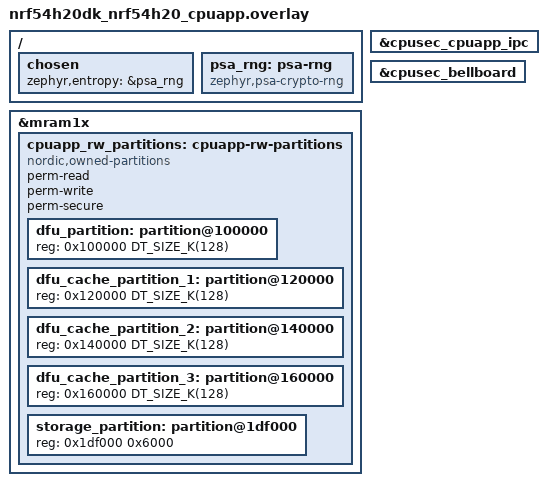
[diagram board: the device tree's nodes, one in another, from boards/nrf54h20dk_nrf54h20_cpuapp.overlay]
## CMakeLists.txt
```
#
# Copyright (c) 2023 Nordic Semiconductor
#
# SPDX-License-Identifier: LicenseRef-Nordic-5-Clause
#

cmake_minimum_required(VERSION 3.20.0)

find_package(Zephyr REQUIRED HINTS $ENV{ZEPHYR_BASE})
project(dfu_target_suit_test)

FILE(GLOB app_sources src/*.c)
target_sources(app PRIVATE ${app_sources})

set(includes
"src/"
)

target_include_directories(app
  PRIVATE
  ${ZEPHYR_NRF_MODULE_DIR}/subsys/dfu/include
  ${includes}
  )

# Mandatory stubbed flags for building test setup
target_compile_options(app
  PRIVATE
  -DCONFIG_DFU_TARGET_LOG_LEVEL=2
  -DCONFIG_DFU_TARGET_SMP=1
  -DCONFIG_DFU_TARGET_SMP_IMAGE_LIST_SIZE=2
  )
```

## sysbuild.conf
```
#
# Copyright (c) 2024 Nordic Semiconductor ASA
#
# SPDX-License-Identifier: LicenseRef-Nordic-5-Clause
#

# SB_CONFIG_SUIT_ENVELOPE=y
```

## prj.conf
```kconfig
#
# Copyright (c) 2024 Nordic Semiconductor ASA
#
# SPDX-License-Identifier: LicenseRef-Nordic-5-Clause
#
CONFIG_ZTEST=y

# Enable suit
CONFIG_SUIT=y
CONFIG_SUIT_DFU=y

# Enable dfu_target
CONFIG_DFU_TARGET=y
CONFIG_DFU_TARGET_SUIT=y

# Initialize SUIT DFU by dfu_target since it is the only 
# one SUIT DFU implementation in use
CONFIG_DFU_TARGET_SUIT_INITIALIZE_SUIT=y

# Choose SUIT platform APP
CONFIG_SUIT_PLATFORM_VARIANT_APP=y
```

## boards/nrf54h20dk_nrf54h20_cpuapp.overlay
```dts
/*
 * Copyright (c) 2024 Nordic Semiconductor ASA
 *
 * SPDX-License-Identifier: LicenseRef-Nordic-5-Clause
 */

/ {
	chosen {
		zephyr,entropy = &psa_rng;
	};

	psa_rng: psa-rng {
		compatible = "zephyr,psa-crypto-rng";
		status = "okay";
	};
};

/* Split DFU partition into a smaller one and DFU caches. */
/delete-node/ &dfu_partition;
/delete-node/ &storage_partition;

&mram1x {
	cpuapp_rw_partitions: cpuapp-rw-partitions {
		compatible = "nordic,owned-partitions", "fixed-partitions";
		status = "okay";
		perm-read;
		perm-write;
		perm-secure;
		#address-cells = < 0x1 >;
		#size-cells = < 0x1 >;

		dfu_partition: partition@100000 {
			reg = < 0x100000 DT_SIZE_K(128) >;
		};

		dfu_cache_partition_1: partition@120000 {
			reg = <0x120000 DT_SIZE_K(128)>;
		};

		dfu_cache_partition_2: partition@140000 {
			reg = <0x140000 DT_SIZE_K(128)>;
		};

		dfu_cache_partition_3: partition@160000 {
			reg = <0x160000 DT_SIZE_K(128)>;
		};

		storage_partition: partition@1df000 {
			reg = < 0x1df000 0x6000 >;
		};
	};
};

/* Communication between Application Core and Secure domain for SUIT */
&cpusec_cpuapp_ipc {
	status = "okay";
};
&cpusec_bellboard {
	status = "okay";
};
```

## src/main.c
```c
/*
 * Copyright (c) 2023 Nordic Semiconductor ASA
 *
 * SPDX-License-Identifier: LicenseRef-Nordic-5-Clause
 */

#include <zephyr/ztest.h>
#include <dfu/dfu_target.h>
#include <dfu/dfu_target_suit.h>
#include <zephyr/devicetree.h>

#define TEST_IMAGE_SIZE		1024
#define TEST_IMAGE_ENVELOPE_NUM 0
#define TEST_IMAGE_APP_NUM	2

static uint8_t dfu_target_buffer[TEST_IMAGE_SIZE];

/* The SUIT envelopes are defined inside the respective manfest_*.c files. */
extern uint8_t manifest[];
extern const size_t manifest_len;
extern uint8_t dfu_cache_partition_1[];
extern const size_t dfu_cache_partition_1_len;

ZTEST(dfu_target_suit, test_image_init)
{
	int rc;

	rc = dfu_target_suit_reset();
	zassert_equal(rc, 0, "Unexpected failure: %d", rc);

	rc = dfu_target_init(DFU_TARGET_IMAGE_TYPE_SUIT, TEST_IMAGE_ENVELOPE_NUM, TEST_IMAGE_SIZE,
			     NULL);
	zassert_equal(rc, -ENODEV,
		      "dfu_target should fail because the buffer has not been initialized. %d", rc);

	rc = dfu_target_suit_set_buf(dfu_target_buffer, sizeof(dfu_target_buffer));
	zassert_equal(rc, 0, "dfu_target should initialize the data buffer %d", rc);

	rc = dfu_target_init(DFU_TARGET_IMAGE_TYPE_SUIT, TEST_IMAGE_ENVELOPE_NUM,
			     TEST_IMAGE_SIZE * 1000, NULL);
	zassert_equal(rc, -EFBIG, "dfu_target should not allow too big files. %d", rc);

	rc = dfu_target_init(DFU_TARGET_IMAGE_TYPE_SUIT, TEST_IMAGE_ENVELOPE_NUM, TEST_IMAGE_SIZE,
			     NULL);
	zassert_equal(rc, 0, "Unexpected failure: %d", rc);

	rc = dfu_target_init(DFU_TARGET_IMAGE_TYPE_SUIT, TEST_IMAGE_ENVELOPE_NUM, TEST_IMAGE_SIZE,
			     NULL);
	zassert_equal(rc, -EBUSY,
		      "dfu_target should not initialize the same image twice until the stream is "
		      "not ended or reset. %d",
		      rc);

	rc = dfu_target_suit_reset();
	zassert_equal(rc, 0, "Unexpected failure: %d", rc);

	rc = dfu_target_init(DFU_TARGET_IMAGE_TYPE_SUIT, TEST_IMAGE_APP_NUM, TEST_IMAGE_SIZE, NULL);
	zassert_equal(rc, 0, "Unexpected failure: %d", rc);
}

ZTEST(dfu_target_suit, test_image_upload)
{
	int rc;
	size_t offset = 0;

	rc = dfu_target_suit_reset();
	zassert_equal(rc, 0, "Unexpected failure: %d", rc);

	rc = dfu_target_suit_write(manifest, TEST_IMAGE_SIZE);
	zassert_equal(rc, -EFAULT, "Unexpected failure: %d", rc);

	rc = dfu_target_suit_schedule_update(0);
	zassert_equal(rc, -ENOTSUP,
		      "scheduling update should file because there is no manifest stored yet: %d",
		      rc);

	rc = dfu_target_suit_offset_get(&offset);
	zassert_equal(rc, 0, "Unexpected failure: %d", rc);
	zassert_equal(offset, 0, "DFU target offset should be equal to 0");

	rc = dfu_target_init(DFU_TARGET_IMAGE_TYPE_SUIT, TEST_IMAGE_ENVELOPE_NUM, manifest_len,
			     NULL);
	zassert_equal(rc, 0, "Unexpected failure: %d", rc);

	rc = dfu_target_suit_write(manifest, manifest_len);
	zassert_equal(rc, 0, "Unexpected failure: %d", rc);

	rc = dfu_target_suit_offset_get(&offset);
	zassert_equal(rc, 0, "DFU target offset get should pass for image 0 %d", rc);
	zassert_equal(offset, manifest_len, "DFU target offset should be equal to image size");

	rc = dfu_target_done(true);
	zassert_equal(rc, 0, "Unexpected failure: %d", rc);

	rc = dfu_target_init(DFU_TARGET_IMAGE_TYPE_SUIT, TEST_IMAGE_APP_NUM,
			     dfu_cache_partition_1_len, NULL);
	zassert_equal(rc, 0, "Unexpected failure: %d", rc);

	rc = dfu_target_suit_write(dfu_cache_partition_1, dfu_cache_partition_1_len);
	zassert_equal(rc, 0, "Unexpected failure: %d", rc);

	rc = dfu_target_suit_offset_get(&offset);
	zassert_equal(rc, 0, "DFU target offset get should pass for image 0 %d", rc);
	zassert_equal(offset, dfu_cache_partition_1_len,
		      "DFU target offset should be equal to image size");

	rc = dfu_target_done(true);
	zassert_equal(rc, 0, "Unexpected failure: %d", rc);

	rc = dfu_target_suit_schedule_update(0);
	zassert_equal(rc, 0, "Unexpected failure: %d", rc);
}

ZTEST_SUITE(dfu_target_suit, NULL, NULL, NULL, NULL, NULL);
```

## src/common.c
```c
/*
 * Copyright (c) 2024 Nordic Semiconductor ASA
 *
 * SPDX-License-Identifier: LicenseRef-Nordic-5-Clause
 */

#include "common.h"

/* Mocks - ssf services have to be mocked, as real communication with secure domain
 * cannot take place in these tests because native_posix target does not have the secure domain
 * to communicate with, and nRF54H should not reset the device after calling
 * the dfu_target_suit_schedule_update function.
 */
DEFINE_FFF_GLOBALS;

/* Mocks of functions provided via SSF services */
#ifdef CONFIG_SOC_POSIX
FAKE_VALUE_FUNC(int, suit_plat_component_compatibility_check, suit_manifest_class_id_t *,
		struct zcbor_string *);
FAKE_VALUE_FUNC(int, suit_plat_authorize_sequence_num, enum suit_command_sequence,
		struct zcbor_string *, unsigned int);
FAKE_VALUE_FUNC(int, suit_plat_authorize_unsigned_manifest, struct zcbor_string *);
FAKE_VALUE_FUNC(int, suit_plat_authenticate_manifest, struct zcbor_string *, enum suit_cose_alg,
		struct zcbor_string *, struct zcbor_string *, struct zcbor_string *);

FAKE_VALUE_FUNC(suit_ssf_err_t, suit_check_installed_component_digest, suit_plat_mreg_t *, int,
		suit_plat_mreg_t *);
FAKE_VALUE_FUNC(suit_ssf_err_t, suit_get_supported_manifest_roles, suit_manifest_role_t *,
		size_t *);
FAKE_VALUE_FUNC(suit_ssf_err_t, suit_get_supported_manifest_info, suit_manifest_role_t,
		suit_ssf_manifest_class_info_t *);
FAKE_VALUE_FUNC(suit_ssf_err_t, suit_get_installed_manifest_info, suit_manifest_class_id_t *,
		unsigned int *, suit_semver_raw_t *, suit_digest_status_t *, int *,
		suit_plat_mreg_t *);
#endif

DEFINE_FAKE_VALUE_FUNC(int, suit_trigger_update, suit_plat_mreg_t *, size_t);

void reset_fakes(void)
{
	#ifdef CONFIG_SOC_POSIX
		RESET_FAKE(suit_plat_component_compatibility_check);
		RESET_FAKE(suit_plat_authorize_sequence_num);
		RESET_FAKE(suit_plat_authorize_unsigned_manifest);
		RESET_FAKE(suit_plat_authenticate_manifest);
		RESET_FAKE(suit_check_installed_component_digest);
		RESET_FAKE(suit_get_supported_manifest_roles);
		RESET_FAKE(suit_get_supported_manifest_info);
		RESET_FAKE(suit_get_installed_manifest_info);
	#endif /* CONFIG_SOC_POSIX */
	
	RESET_FAKE(suit_trigger_update);
}
```

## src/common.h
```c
/*
 * Copyright (c) 2024 Nordic Semiconductor ASA
 *
 * SPDX-License-Identifier: LicenseRef-Nordic-5-Clause
 */

#ifndef DFU_TARGET_SUIT_TEST_COMMON_H__
#define DFU_TARGET_SUIT_TEST_COMMON_H__

#include <stdint.h>
#include <stddef.h>

#include <sdfw/sdfw_services/suit_service.h>
#include <suit_plat_mem_util.h>
#include <suit_platform.h>

#include <zephyr/ztest.h>
#include <zephyr/devicetree.h>
#include <zephyr/fff.h>

/**
 * @brief Reset all mocked functions.
 *
 */
void reset_fakes(void);

DECLARE_FAKE_VALUE_FUNC(int, suit_trigger_update, suit_plat_mreg_t *, size_t);

#endif // DFU_TARGET_SUIT_TEST_COMMON_H__
```

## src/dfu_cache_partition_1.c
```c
/*
 * Copyright (c) 2024 Nordic Semiconductor ASA
 *
 * SPDX-License-Identifier: LicenseRef-Nordic-5-Clause
 */

#include <stdint.h>
#include <stddef.h>

uint8_t dfu_cache_partition_1[] = {
	0xBF, 0x69, 0x23, 0x66, 0x69, 0x6C, 0x65, 0x2E, 0x62, 0x69, 0x6E, 0x5A, 0x00, 0x00, 0x01,
	0x00, 0xC7, 0x9C, 0xAB, 0x9D, 0xE8, 0x33, 0x7F, 0x30, 0x14, 0xEB, 0xAC, 0x02, 0xAF, 0x26,
	0x01, 0x5E, 0x80, 0x6D, 0x88, 0xA1, 0xDB, 0x11, 0xA7, 0x31, 0xDF, 0xA6, 0xEC, 0xCB, 0x9B,
	0x48, 0x0D, 0xC8, 0x34, 0x40, 0x6D, 0x30, 0x86, 0x7D, 0xE8, 0x1B, 0xEC, 0x3C, 0xF5, 0x40,
	0xD0, 0x48, 0x18, 0x82, 0x11, 0x9D, 0x7C, 0x3F, 0x6C, 0xE5, 0x8F, 0xF1, 0xD3, 0x5D, 0xE1,
	0x51, 0xF7, 0x6A, 0x0F, 0xAF, 0x0B, 0xBD, 0x4C, 0x5F, 0xA5, 0x34, 0x1A, 0x66, 0xDB, 0x22,
	0xEC, 0x63, 0xED, 0x4B, 0xAB, 0xC7, 0xC8, 0xF7, 0x59, 0xD8, 0xD6, 0x9E, 0xEC, 0x71, 0x1B,
	0x24, 0x20, 0xB9, 0xAE, 0xE1, 0x3B, 0xFC, 0xAE, 0xB8, 0x77, 0xAC, 0xA4, 0x57, 0x34, 0x97,
	0x84, 0x4F, 0x58, 0xD5, 0x68, 0x08, 0x6F, 0xE3, 0x9C, 0x7E, 0x1B, 0xD7, 0x38, 0x22, 0x98,
	0x48, 0xF8, 0x7A, 0x67, 0xB2, 0xD9, 0xAC, 0xC5, 0x34, 0xC1, 0x27, 0x82, 0x8E, 0x42, 0x79,
	0x84, 0x21, 0x37, 0x4C, 0x41, 0x4A, 0x0F, 0xE2, 0x7F, 0xA0, 0x6A, 0x19, 0x13, 0x3D, 0x52,
	0x22, 0x7F, 0xD6, 0x2F, 0x71, 0x12, 0x76, 0xAB, 0x25, 0x9C, 0xFC, 0x67, 0x08, 0x03, 0x7C,
	0xDB, 0x18, 0xE6, 0x45, 0xF8, 0x99, 0xC2, 0x9E, 0x2C, 0xE3, 0x9B, 0x25, 0xA9, 0x7B, 0x09,
	0xFF, 0x00, 0x57, 0x26, 0x08, 0x0A, 0x11, 0x42, 0xCF, 0x82, 0xA2, 0x6B, 0x2A, 0x99, 0xF9,
	0x71, 0x9D, 0x14, 0x19, 0x5C, 0x5C, 0x78, 0x31, 0x60, 0x42, 0x4A, 0x18, 0x1F, 0xEC, 0x78,
	0x6A, 0x9A, 0x7C, 0x4F, 0xCF, 0xE8, 0x5A, 0x29, 0x65, 0xCD, 0x01, 0x3B, 0x6D, 0x53, 0xBB,
	0xC6, 0xDB, 0xDA, 0xD5, 0x8F, 0xF7, 0xF4, 0xD9, 0xB9, 0x0A, 0x03, 0x4B, 0xFF, 0x33, 0xAB,
	0x3B, 0xC5, 0xAF, 0xD0, 0xB8, 0x2C, 0x0F, 0x6A, 0xA9, 0x11, 0xB0, 0xE8, 0x57, 0x8C, 0x92,
	0x53, 0x81, 0xFF};

const size_t dfu_cache_partition_1_len = sizeof(dfu_cache_partition_1);
```

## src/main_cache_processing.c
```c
/*
 * Copyright (c) 2024 Nordic Semiconductor ASA
 *
 * SPDX-License-Identifier: LicenseRef-Nordic-5-Clause
 */

#if CONFIG_TESTS_SUIT_DFU_TARGET_SUIT_CACHE_PROCESSING

#include <dfu/dfu_target.h>
#include <dfu/dfu_target_suit.h>

#include "common.h"

/* The SUIT envelopes are defined inside the respective manfest_*.c files. */
extern uint8_t manifest[];
extern const size_t manifest_len;
extern uint8_t dfu_cache_partition_1[];
extern const size_t dfu_cache_partition_1_len;
extern uint8_t manifest_with_payload[];
extern const size_t manifest_with_payload_len;

#define TEST_IMAGE_SIZE		1024
#define TEST_IMAGE_ENVELOPE_NUM 0
#define TEST_IMAGE_APP_NUM	2

static uint8_t dfu_target_buffer[TEST_IMAGE_SIZE];

static void setup_test(void *f)
{
	(void)f;

	reset_fakes();
}

ZTEST(dfu_target_suit, test_image_init)
{
	int rc;

	rc = dfu_target_suit_reset();
	zassert_equal(rc, 0, "Unexpected failure: %d", rc);

	rc = dfu_target_init(DFU_TARGET_IMAGE_TYPE_SUIT, TEST_IMAGE_ENVELOPE_NUM, TEST_IMAGE_SIZE,
			     NULL);
	zassert_equal(rc, -ENODEV,
		      "dfu_target should fail because the buffer has not been initialized. %d", rc);

	rc = dfu_target_suit_set_buf(dfu_target_buffer, sizeof(dfu_target_buffer));
	zassert_equal(rc, 0, "dfu_target should initialize the data buffer %d", rc);

	rc = dfu_target_init(DFU_TARGET_IMAGE_TYPE_SUIT, TEST_IMAGE_ENVELOPE_NUM,
			     TEST_IMAGE_SIZE * 1000, NULL);
	zassert_equal(rc, -EFBIG, "dfu_target should not allow too big files. %d", rc);

	rc = dfu_target_init(DFU_TARGET_IMAGE_TYPE_SUIT, TEST_IMAGE_ENVELOPE_NUM, TEST_IMAGE_SIZE,
			     NULL);
	zassert_equal(rc, 0, "Unexpected failure: %d", rc);

	rc = dfu_target_init(DFU_TARGET_IMAGE_TYPE_SUIT, TEST_IMAGE_ENVELOPE_NUM, TEST_IMAGE_SIZE,
			     NULL);
	zassert_equal(rc, -EBUSY,
		      "dfu_target should not initialize the same image twice until the stream is "
		      "not ended or reset. %d",
		      rc);

	rc = dfu_target_suit_reset();
	zassert_equal(rc, 0, "Unexpected failure: %d", rc);

	rc = dfu_target_init(DFU_TARGET_IMAGE_TYPE_SUIT, TEST_IMAGE_APP_NUM, TEST_IMAGE_SIZE, NULL);
	zassert_equal(rc, 0, "Unexpected failure: %d", rc);
}

ZTEST(dfu_target_suit, test_image_upload)
{
	int rc;
	size_t offset = 0;

	rc = dfu_target_suit_reset();
	zassert_equal(rc, 0, "Unexpected failure: %d", rc);

	rc = dfu_target_suit_write(manifest, TEST_IMAGE_SIZE);
	zassert_equal(rc, -EFAULT, "Unexpected failure: %d", rc);

	rc = dfu_target_suit_schedule_update(0);
	zassert_equal(rc, -ENOTSUP,
		      "scheduling update should file because there is no manifest stored yet: %d",
		      rc);

	rc = dfu_target_suit_offset_get(&offset);
	zassert_equal(rc, 0, "Unexpected failure: %d", rc);
	zassert_equal(offset, 0, "DFU target offset should be equal to 0");

	rc = dfu_target_init(DFU_TARGET_IMAGE_TYPE_SUIT, TEST_IMAGE_ENVELOPE_NUM, manifest_len,
			     NULL);
	zassert_equal(rc, 0, "Unexpected failure: %d", rc);

	rc = dfu_target_suit_write(manifest, manifest_len);
	zassert_equal(rc, 0, "Unexpected failure: %d", rc);

	rc = dfu_target_suit_offset_get(&offset);
	zassert_equal(rc, 0, "DFU target offset get should pass for image 0 %d", rc);
	zassert_equal(offset, manifest_len, "DFU target offset should be equal to image size");

	rc = dfu_target_done(true);
	zassert_equal(rc, 0, "Unexpected failure: %d", rc);

	rc = dfu_target_init(DFU_TARGET_IMAGE_TYPE_SUIT, TEST_IMAGE_APP_NUM,
			     dfu_cache_partition_1_len, NULL);
	zassert_equal(rc, 0, "Unexpected failure: %d", rc);

	rc = dfu_target_suit_write(dfu_cache_partition_1, dfu_cache_partition_1_len);
	zassert_equal(rc, 0, "Unexpected failure: %d", rc);

	rc = dfu_target_suit_offset_get(&offset);
	zassert_equal(rc, 0, "DFU target offset get should pass for image 0 %d", rc);
	zassert_equal(offset, dfu_cache_partition_1_len,
		      "DFU target offset should be equal to image size");

	rc = dfu_target_done(true);
	zassert_equal(rc, 0, "Unexpected failure: %d", rc);

	rc = dfu_target_suit_schedule_update(0);
	zassert_equal(rc, 0, "Unexpected failure: %d", rc);

	dfu_target_suit_reboot();
	zassert_equal(suit_trigger_update_fake.call_count, 1,
		      "Incorrect number of suit_dfu_update_start() calls");
}

ZTEST_SUITE(dfu_target_suit, NULL, NULL, setup_test, NULL, NULL);

#endif /* CONFIG_TESTS_SUIT_DFU_TARGET_SUIT_CACHE_PROCESSING */
```

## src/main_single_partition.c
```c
/*
 * Copyright (c) 2024 Nordic Semiconductor ASA
 *
 * SPDX-License-Identifier: LicenseRef-Nordic-5-Clause
 */

#if CONFIG_TESTS_SUIT_DFU_TARGET_SUIT_SINGLE_PARTITION

#include <dfu/dfu_target.h>
#include <dfu/dfu_target_suit.h>

#include "common.h"

/* The SUIT envelopes are defined inside the respective manfest_*.c files. */
extern uint8_t manifest[];
extern const size_t manifest_len;

#define TEST_IMAGE_SIZE		 1024
#define TEST_IMAGE_ENVELOPE_NUM	 0
#define TEST_WRONG_IMAGE_CACHE_0 1
#define TEST_WRONG_IMAGE_CACHE_1 2

static uint8_t dfu_target_buffer[TEST_IMAGE_SIZE];

static void setup_test(void *f)
{
	(void)f;

	reset_fakes();
}

ZTEST(dfu_target_suit, test_image_init)
{
	int rc;

	rc = dfu_target_suit_reset();
	zassert_equal(rc, 0, "Unexpected failure: %d", rc);

	rc = dfu_target_init(DFU_TARGET_IMAGE_TYPE_SUIT, TEST_IMAGE_ENVELOPE_NUM, TEST_IMAGE_SIZE,
			     NULL);
	zassert_equal(rc, -ENODEV,
		      "dfu_target should fail because the buffer has not been initialized. %d", rc);

	rc = dfu_target_suit_set_buf(dfu_target_buffer, sizeof(dfu_target_buffer));
	zassert_equal(rc, 0, "dfu_target should initialize the data buffer %d", rc);

	rc = dfu_target_init(DFU_TARGET_IMAGE_TYPE_SUIT, TEST_IMAGE_ENVELOPE_NUM, TEST_IMAGE_SIZE,
			     NULL);
	zassert_equal(rc, 0, "Unexpected failure: %d", rc);

	rc = dfu_target_init(DFU_TARGET_IMAGE_TYPE_SUIT, TEST_WRONG_IMAGE_CACHE_0, TEST_IMAGE_SIZE,
			     NULL);
	zassert_equal(rc, -ENOTSUP,
		      "dfu_target should fail because CACHE PROCESSING is not enabled: %d", rc);

	rc = dfu_target_init(DFU_TARGET_IMAGE_TYPE_SUIT, TEST_WRONG_IMAGE_CACHE_1, TEST_IMAGE_SIZE,
			     NULL);
	zassert_equal(rc, -ENOTSUP,
		      "dfu_target should fail because CACHE PROCESSING is not enabled: %d", rc);
}

ZTEST(dfu_target_suit, test_upload)
{
	int rc;
	size_t offset = 0;

	rc = dfu_target_suit_reset();
	zassert_equal(rc, 0, "Unexpected failure: %d", rc);

	rc = dfu_target_suit_set_buf(dfu_target_buffer, sizeof(dfu_target_buffer));
	zassert_equal(rc, 0, "dfu_target should initialize the data buffer %d", rc);

	rc = dfu_target_init(DFU_TARGET_IMAGE_TYPE_SUIT, TEST_IMAGE_ENVELOPE_NUM,
			     TEST_IMAGE_SIZE * 1000, NULL);
	zassert_equal(rc, -EFBIG, "dfu_target should not allow too big files. %d", rc);

	rc = dfu_target_init(DFU_TARGET_IMAGE_TYPE_SUIT, TEST_IMAGE_ENVELOPE_NUM, TEST_IMAGE_SIZE,
			     NULL);
	zassert_equal(rc, 0, "Unexpected failure: %d", rc);

	rc = dfu_target_suit_write(manifest, manifest_len);
	zassert_equal(rc, 0, "Unexpected failure: %d", rc);

	rc = dfu_target_suit_offset_get(&offset);
	zassert_equal(rc, 0, "DFU target offset get should pass for image 0 %d", rc);
	zassert_equal(offset, manifest_len, "DFU target offset should be equal to image size");

	rc = dfu_target_done(true);
	zassert_equal(rc, 0, "Unexpected failure: %d", rc);

	rc = dfu_target_suit_schedule_update(0);
	zassert_equal(rc, 0, "Unexpected failure: %d", rc);

	dfu_target_suit_reboot();
	zassert_equal(suit_trigger_update_fake.call_count, 1,
		      "Incorrect number of suit_trigger_update() calls");
}

ZTEST_SUITE(dfu_target_suit, NULL, NULL, setup_test, NULL, NULL);

#endif /* CONFIG_TESTS_SUIT_DFU_TARGET_SUIT_SINGLE_PARTITION */
```

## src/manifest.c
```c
/*
 * Copyright (c) 2024 Nordic Semiconductor ASA
 *
 * SPDX-License-Identifier: LicenseRef-Nordic-5-Clause
 */

#include <stdint.h>
#include <stddef.h>

uint8_t manifest[] = {
	0xD8, 0x6B, 0xA2, 0x02, 0x58, 0x7A, 0x82, 0x58, 0x24, 0x82, 0x2F, 0x58, 0x20, 0x95, 0x05,
	0x04, 0xEE, 0x94, 0x60, 0x07, 0xDE, 0xC6, 0xB6, 0x00, 0xA0, 0xAD, 0x95, 0x7F, 0x96, 0xEA,
	0x02, 0x5A, 0x49, 0x82, 0xE8, 0xB3, 0xCA, 0x22, 0xF9, 0xA4, 0x55, 0x2E, 0x0B, 0xB6, 0xF3,
	0x58, 0x51, 0xD2, 0x84, 0x4A, 0xA2, 0x01, 0x26, 0x04, 0x45, 0x1A, 0x7F, 0xFF, 0xFF, 0xE0,
	0xA0, 0xF6, 0x58, 0x40, 0x0D, 0x73, 0xF3, 0xFB, 0xEA, 0x1A, 0xC1, 0x42, 0x54, 0xF2, 0x0A,
	0xFD, 0xDC, 0x8A, 0xD5, 0x61, 0xDB, 0xA3, 0x86, 0xE3, 0xBB, 0x70, 0x2E, 0xCF, 0x21, 0x3E,
	0xC0, 0x93, 0xA6, 0x6E, 0x80, 0xA1, 0x68, 0xFD, 0xA1, 0x2A, 0xA3, 0xAE, 0xFD, 0x9A, 0x67,
	0x24, 0x40, 0x38, 0x64, 0x51, 0x26, 0xF0, 0x9B, 0x3C, 0xC6, 0xF9, 0xF2, 0x6D, 0x74, 0xE5,
	0xB0, 0x57, 0x74, 0x53, 0x2D, 0xAB, 0x97, 0x7A, 0x03, 0x58, 0xBA, 0xA8, 0x01, 0x01, 0x02,
	0x01, 0x03, 0x58, 0x70, 0xA2, 0x02, 0x81, 0x84, 0x44, 0x63, 0x4D, 0x45, 0x4D, 0x41, 0x02,
	0x45, 0x1A, 0x0E, 0x16, 0x00, 0x00, 0x45, 0x1A, 0x00, 0x02, 0x00, 0x00, 0x04, 0x58, 0x56,
	0x86, 0x14, 0xA4, 0x01, 0x50, 0x76, 0x17, 0xDA, 0xA5, 0x71, 0xFD, 0x5A, 0x85, 0x8F, 0x94,
	0xE2, 0x8D, 0x73, 0x5C, 0xE9, 0xF4, 0x02, 0x50, 0xBA, 0x6C, 0x70, 0x4B, 0x1F, 0xD9, 0x5F,
	0x78, 0x91, 0x35, 0xBF, 0x04, 0xD9, 0xA4, 0xED, 0x31, 0x03, 0x58, 0x24, 0x82, 0x2F, 0x58,
	0x20, 0x5F, 0xC3, 0x54, 0xBF, 0x8E, 0x8C, 0x50, 0xFB, 0x4F, 0xBC, 0x2C, 0xFA, 0xEB, 0x04,
	0x53, 0x41, 0xC9, 0x80, 0x6D, 0xEA, 0xBD, 0xCB, 0x41, 0x54, 0xFB, 0x79, 0xCC, 0xA4, 0xF0,
	0xC9, 0x8C, 0x12, 0x0E, 0x19, 0x01, 0x00, 0x01, 0x0F, 0x02, 0x0F, 0x07, 0x43, 0x82, 0x03,
	0x0F, 0x09, 0x43, 0x82, 0x17, 0x02, 0x11, 0x52, 0x86, 0x14, 0xA1, 0x15, 0x69, 0x23, 0x66,
	0x69, 0x6C, 0x65, 0x2E, 0x62, 0x69, 0x6E, 0x15, 0x02, 0x03, 0x0F, 0x17, 0x82, 0x2F, 0x40,
	0x05, 0x82, 0x4C, 0x6B, 0x49, 0x4E, 0x53, 0x54, 0x4C, 0x44, 0x5F, 0x4D, 0x46, 0x53, 0x54,
	0x50, 0x08, 0xC1, 0xB5, 0x99, 0x55, 0xE8, 0x5F, 0xBC, 0x9E, 0x76, 0x7B, 0xC2, 0x9C, 0xE1,
	0xB0, 0x4D};

const size_t manifest_len = sizeof(manifest);
```

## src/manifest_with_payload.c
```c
/*
 * Copyright (c) 2024 Nordic Semiconductor ASA
 *
 * SPDX-License-Identifier: LicenseRef-Nordic-5-Clause
 */

#include <stdint.h>
#include <stddef.h>

uint8_t manifest_with_payload[] = {
	0xD8, 0x6B, 0xA3, 0x02, 0x58, 0x7A, 0x82, 0x58, 0x24, 0x82, 0x2F, 0x58, 0x20, 0x11, 0x8E,
	0x39, 0xBF, 0x66, 0x05, 0x50, 0xEC, 0x92, 0xB0, 0xAC, 0x79, 0x87, 0xBB, 0x60, 0x0B, 0x26,
	0x9B, 0x96, 0xEF, 0x60, 0xC2, 0xCA, 0xCD, 0x74, 0x23, 0x51, 0x82, 0x96, 0xFE, 0x54, 0x9B,
	0x58, 0x51, 0xD2, 0x84, 0x4A, 0xA2, 0x01, 0x26, 0x04, 0x45, 0x1A, 0x7F, 0xFF, 0xFF, 0xE0,
	0xA0, 0xF6, 0x58, 0x40, 0xF9, 0xB3, 0xEB, 0x08, 0x51, 0xAB, 0x88, 0xD0, 0x96, 0x29, 0x1B,
	0x2A, 0x9A, 0x75, 0xB7, 0xE5, 0x3C, 0x25, 0x24, 0xC7, 0x7E, 0x7D, 0x88, 0x58, 0x21, 0x39,
	0x4E, 0x14, 0x6B, 0xA1, 0x8D, 0xAB, 0xA7, 0xE5, 0x13, 0xBC, 0xE7, 0xD5, 0x3D, 0x57, 0xF8,
	0x5F, 0xF3, 0xB9, 0x6C, 0x84, 0xAE, 0xE5, 0xAB, 0xC3, 0x30, 0x3F, 0xCA, 0xAB, 0x2F, 0x3A,
	0x07, 0xDA, 0xF5, 0x7A, 0xB3, 0xC1, 0xC4, 0x75, 0x03, 0x58, 0xBA, 0xA8, 0x01, 0x01, 0x02,
	0x01, 0x03, 0x58, 0x70, 0xA2, 0x02, 0x81, 0x84, 0x44, 0x63, 0x4D, 0x45, 0x4D, 0x41, 0x02,
	0x45, 0x1A, 0x0E, 0x16, 0x00, 0x00, 0x45, 0x1A, 0x00, 0x02, 0x00, 0x00, 0x04, 0x58, 0x56,
	0x86, 0x14, 0xA4, 0x01, 0x50, 0x76, 0x17, 0xDA, 0xA5, 0x71, 0xFD, 0x5A, 0x85, 0x8F, 0x94,
	0xE2, 0x8D, 0x73, 0x5C, 0xE9, 0xF4, 0x02, 0x50, 0xBA, 0x6C, 0x70, 0x4B, 0x1F, 0xD9, 0x5F,
	0x78, 0x91, 0x35, 0xBF, 0x04, 0xD9, 0xA4, 0xED, 0x31, 0x03, 0x58, 0x24, 0x82, 0x2F, 0x58,
	0x20, 0x5F, 0xC3, 0x54, 0xBF, 0x8E, 0x8C, 0x50, 0xFB, 0x4F, 0xBC, 0x2C, 0xFA, 0xEB, 0x04,
	0x53, 0x41, 0xC9, 0x80, 0x6D, 0xEA, 0xBD, 0xCB, 0x41, 0x54, 0xFB, 0x79, 0xCC, 0xA4, 0xF0,
	0xC9, 0x8C, 0x12, 0x0E, 0x19, 0x01, 0x00, 0x01, 0x0F, 0x02, 0x0F, 0x07, 0x43, 0x82, 0x03,
	0x0F, 0x09, 0x43, 0x82, 0x17, 0x02, 0x11, 0x52, 0x86, 0x14, 0xA1, 0x15, 0x69, 0x23, 0x66,
	0x69, 0x6C, 0x65, 0x2E, 0x62, 0x69, 0x6E, 0x15, 0x02, 0x03, 0x0F, 0x17, 0x82, 0x2F, 0x40,
	0x05, 0x82, 0x4C, 0x6B, 0x49, 0x4E, 0x53, 0x54, 0x4C, 0x44, 0x5F, 0x4D, 0x46, 0x53, 0x54,
	0x50, 0x5B, 0x46, 0x9F, 0xD1, 0x90, 0xEE, 0x53, 0x9C, 0xA3, 0x18, 0x68, 0x1B, 0x03, 0x69,
	0x5E, 0x36, 0x69, 0x23, 0x66, 0x69, 0x6C, 0x65, 0x2E, 0x62, 0x69, 0x6E, 0x59, 0x01, 0x00,
	0xC7, 0x9C, 0xAB, 0x9D, 0xE8, 0x33, 0x7F, 0x30, 0x14, 0xEB, 0xAC, 0x02, 0xAF, 0x26, 0x01,
	0x5E, 0x80, 0x6D, 0x88, 0xA1, 0xDB, 0x11, 0xA7, 0x31, 0xDF, 0xA6, 0xEC, 0xCB, 0x9B, 0x48,
	0x0D, 0xC8, 0x34, 0x40, 0x6D, 0x30, 0x86, 0x7D, 0xE8, 0x1B, 0xEC, 0x3C, 0xF5, 0x40, 0xD0,
	0x48, 0x18, 0x82, 0x11, 0x9D, 0x7C, 0x3F, 0x6C, 0xE5, 0x8F, 0xF1, 0xD3, 0x5D, 0xE1, 0x51,
	0xF7, 0x6A, 0x0F, 0xAF, 0x0B, 0xBD, 0x4C, 0x5F, 0xA5, 0x34, 0x1A, 0x66, 0xDB, 0x22, 0xEC,
	0x63, 0xED, 0x4B, 0xAB, 0xC7, 0xC8, 0xF7, 0x59, 0xD8, 0xD6, 0x9E, 0xEC, 0x71, 0x1B, 0x24,
	0x20, 0xB9, 0xAE, 0xE1, 0x3B, 0xFC, 0xAE, 0xB8, 0x77, 0xAC, 0xA4, 0x57, 0x34, 0x97, 0x84,
	0x4F, 0x58, 0xD5, 0x68, 0x08, 0x6F, 0xE3, 0x9C, 0x7E, 0x1B, 0xD7, 0x38, 0x22, 0x98, 0x48,
	0xF8, 0x7A, 0x67, 0xB2, 0xD9, 0xAC, 0xC5, 0x34, 0xC1, 0x27, 0x82, 0x8E, 0x42, 0x79, 0x84,
	0x21, 0x37, 0x4C, 0x41, 0x4A, 0x0F, 0xE2, 0x7F, 0xA0, 0x6A, 0x19, 0x13, 0x3D, 0x52, 0x22,
	0x7F, 0xD6, 0x2F, 0x71, 0x12, 0x76, 0xAB, 0x25, 0x9C, 0xFC, 0x67, 0x08, 0x03, 0x7C, 0xDB,
	0x18, 0xE6, 0x45, 0xF8, 0x99, 0xC2, 0x9E, 0x2C, 0xE3, 0x9B, 0x25, 0xA9, 0x7B, 0x09, 0xFF,
	0x00, 0x57, 0x26, 0x08, 0x0A, 0x11, 0x42, 0xCF, 0x82, 0xA2, 0x6B, 0x2A, 0x99, 0xF9, 0x71,
	0x9D, 0x14, 0x19, 0x5C, 0x5C, 0x78, 0x31, 0x60, 0x42, 0x4A, 0x18, 0x1F, 0xEC, 0x78, 0x6A,
	0x9A, 0x7C, 0x4F, 0xCF, 0xE8, 0x5A, 0x29, 0x65, 0xCD, 0x01, 0x3B, 0x6D, 0x53, 0xBB, 0xC6,
	0xDB, 0xDA, 0xD5, 0x8F, 0xF7, 0xF4, 0xD9, 0xB9, 0x0A, 0x03, 0x4B, 0xFF, 0x33, 0xAB, 0x3B,
	0xC5, 0xAF, 0xD0, 0xB8, 0x2C, 0x0F, 0x6A, 0xA9, 0x11, 0xB0, 0xE8, 0x57, 0x8C, 0x92, 0x53,
	0x81};

const size_t manifest_with_payload_len = sizeof(manifest_with_payload);
```
